# AVR16EB14 device description
Architecture: AVR8X; Family: AVREB
Registers are 8-bit, read-write, reset 0x0 unless marked. A register's access mark holds for its fields unless they carry their own. Offsets are from the block's base; [hi:lo] are bit positions; 'fields as' and 'values as' point back to an identical list.

## TCF — 24-bit Timer/Counter for frequency generation
Instances: TCF0 0x0C00
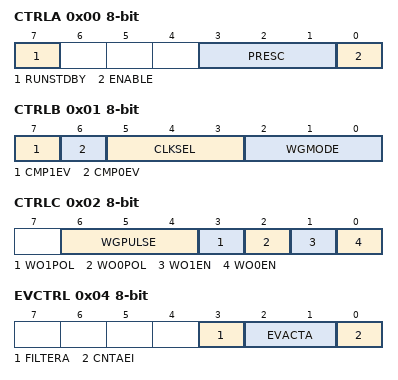
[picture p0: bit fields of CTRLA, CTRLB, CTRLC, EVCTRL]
0x00 CTRLA — Control A
  [7] RUNSTDBY — Run Standby
  [3:1] PRESC — Clock Prescaler
    0=DIV1 (Runs directly on Clock Source); 1=DIV2 (Divide clock source by 2); 2=DIV4 (Divide clock source by 4); 3=DIV8 (Divide clock source by 8); 4=DIV16 (Divide clock source by 16); 5=DIV32 (Divide clock source by 32); 6=DIV64 (Divide clock source by 64); 7=DIV128 (Divide clock source by 128)
  [0] ENABLE
0x01 CTRLB — Control B
  [7] CMP1EV — Compare 1 Event Generation
    0=PULSE (Event is generated as pulse); 1=WAVEFORM (Waveform is used as event output)
  [6] CMP0EV — Compare 0 Event Generation
    values as CMP1EV
  [5:3] CLKSEL — Clock Select
    0=CLKPER (Peripheral Clock); 1=EVENT (Event as clock source); 2=OSCHF (Internal High Frequency Oscillator); 3=OSC32K (Internal 32.768 kHz Oscillator); 5=PLL
  [2:0] WGMODE — Waveform Generation Mode
    0=FRQ (Frequency); 1=NCOPF (Numerically Controlled Oscillator Pulse-Frequency); 2=NCOFDC (Numerically Controlled Oscillator Fixed Duty Cycle); 7=PWM8 (8-bit PWM)
0x02 CTRLC — Control C
  [6:4] WGPULSE — Waveform Generation Pulse Length
    0=CLK1 (High pulse duration is 1 clock period); 1=CLK2 (High pulse duration is 2 clock period); 2=CLK4 (High pulse duration is 4 clock period); 3=CLK8 (High pulse duration is 8 clock period); 4=CLK16 (High pulse duration is 16 clock period); 5=CLK32 (High pulse duration is 32 clock period); 6=CLK64 (High pulse duration is 64 clock period); 7=CLK128 (High pulse duration is 128 clock period)
  [3] WO1POL — Waveform Output 1 Polarity
    0=NORMAL (Waveform output set on update and cleared on match); 1=INVERSE (Waveform output cleared on update and set on match)
  [2] WO0POL — Waveform Output 0 Polarity
    values as WO1POL
  [1] WO1EN — Waveform Output 1 Enable
  [0] WO0EN — Waveform Output 0 Enable
0x03 CTRLD — Control D
  [1:0] CMD — Command
    0=NONE (No command); 1=UPDATE (Force update); 2=RESTART (Force restart)
0x04 EVCTRL — Event Control
  [3] FILTERA — Event A Filter
  [2:1] EVACTA — Event Action A
    0=RESTART (Restart Counter); 1=BLANK (Mask waveform output to '0')
  [0] CNTAEI — Event A Input Enable
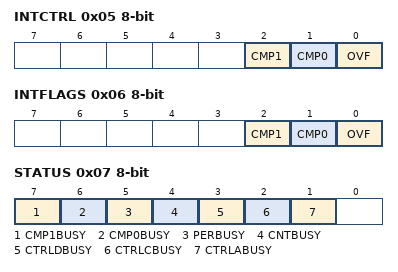
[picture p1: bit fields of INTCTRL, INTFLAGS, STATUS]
0x05 INTCTRL — Interrupt Control
  [2] CMP1 — Compare 1 Interrupt Enable
  [1] CMP0 — Compare 0 Interrupt Enable
  [0] OVF — Overflow
0x06 INTFLAGS — Interrupt Flags
  [2] CMP1 — Compare 1 Flag
  [1] CMP0 — Compare 0 Flag
  [0] OVF — Overflow Flag
0x07 STATUS ro
  [7] CMP1BUSY — Compare 1 Synchronization Busy
  [6] CMP0BUSY — Compare 0 Synchronization Busy
  [5] PERBUSY — Period Synchronization Busy
  [4] CNTBUSY — Counter Synchronization Busy
  [3] CTRLDBUSY — Control D Synchronization Busy
  [2] CTRLCBUSY — Control B Synchronization Busy
  [1] CTRLABUSY — Control A Synchronization Busy
0x0D DBGCTRL — Debug Control
  [0] DBGRUN — Debug Run
0x10 CNT 32-bit — Count
  [23:0] CNT — Counter
0x14 CMP 32-bit — Compare
  [23:0] CMP

## TWI — Two-Wire Interface
Instances: TWI0 0x0900
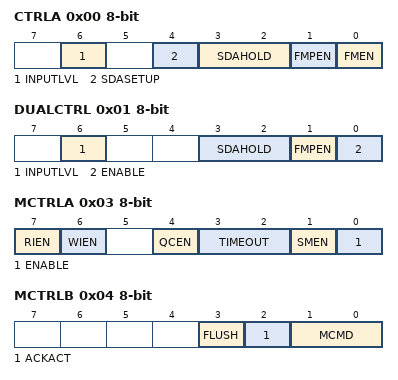
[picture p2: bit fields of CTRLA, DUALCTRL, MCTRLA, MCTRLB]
0x00 CTRLA — Control A
  [6] INPUTLVL — Input voltage transition level
    0=I2C (I2C input voltage transition level); 1=SMBUS (SMBus 3.0 input voltage transition level)
  [4] SDASETUP — SDA Setup Time
    0=4CYC (SDA setup time is four clock cycles); 1=8CYC (SDA setup time is eight clock cycle)
  [3:2] SDAHOLD — SDA Hold Time
    0=OFF (No SDA Hold Delay); 1=50NS (Short SDA hold time); 2=300NS (Meets SMBUS 2.0 specification under typical conditions); 3=500NS (Meets SMBUS 2.0 specificaiton across all corners)
  [1] FMPEN — Fast-mode Plus Enable
    0=OFF (Operating in Standard-mode or Fast-mode); 1=ON (Operating in Fast-mode Plus)
  [0] FMEN — Fast-mode Enable
    0=OFF (SCL duty cycle operating according to Sm specification); 1=ON (SCL duty cycle operating according to Fm specification)
0x01 DUALCTRL — Dual Mode Control
  [6] INPUTLVL — Input voltage transition level
    values as CTRLA.INPUTLVL
  [3:2] SDAHOLD — SDA Hold Time
    values as CTRLA.SDAHOLD
  [1] FMPEN — Fast-mode Plus Enable
    values as CTRLA.FMPEN
  [0] ENABLE
0x02 DBGCTRL — Debug Control
  [0] DBGRUN — Debug Run
    0=HALT (The peripheral is halted in Break Debug mode and ignores events); 1=RUN (The peripheral will continue to run in Break Debug mode when the CPU is halted)
0x03 MCTRLA — Host Control A
  [7] RIEN — Read Interrupt Enable
  [6] WIEN — Write Interrupt Enable
  [4] QCEN — Quick Command Enable
  [3:2] TIMEOUT — Inactive Bus Time-Out
    0=DISABLED (Bus time-out disabled. I2C.); 1=50US (50us - SMBus); 2=100US; 3=200US
  [1] SMEN — Smart Mode Enable
  [0] ENABLE
0x04 MCTRLB — Host Control B
  [3] FLUSH
  [2] ACKACT — Acknowledge Action
    0=ACK (Send ACK); 1=NACK (Send NACK)
  [1:0] MCMD — Command
    0=NOACT (No action); 1=REPSTART (Execute Acknowledge Action followed by repeated Start.); 2=RECVTRANS (Execute Acknowledge Action followed by a byte read/write operation. Read/write is defined by DIR.); 3=STOP (Execute Acknowledge Action followed by issuing a Stop condition.)
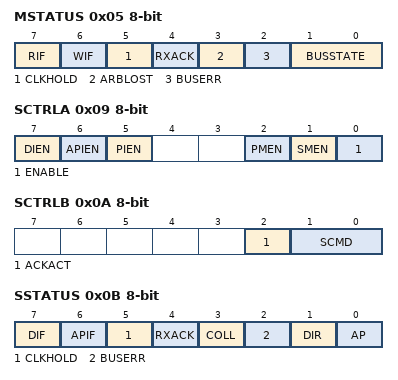
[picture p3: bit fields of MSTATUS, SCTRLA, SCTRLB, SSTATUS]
0x05 MSTATUS — Host STATUS
  [7] RIF — Read Interrupt Flag
  [6] WIF — Write Interrupt Flag
  [5] CLKHOLD — Clock Hold
  [4] RXACK ro — Received Acknowledge
  [3] ARBLOST — Arbitration Lost
  [2] BUSERR — Bus Error
  [1:0] BUSSTATE
    0=UNKNOWN (Unknown bus state); 1=IDLE (Bus is idle); 2=OWNER (This TWI controls the bus); 3=BUSY (The bus is busy)
0x06 MBAUD — Host Baud Rate
  [7:0] BAUD — Baud Rate
0x07 MADDR — Host Address
  [7:0] ADDR — Address
0x08 MDATA — Host Data
  [7:0] DATA
0x09 SCTRLA — Client Control A
  [7] DIEN — Data Interrupt Enable
  [6] APIEN — Address or Stop Interrupt Enable
  [5] PIEN — Stop Interrupt Enable
  [2] PMEN — Address Recognition Mode
  [1] SMEN — Smart Mode Enable
  [0] ENABLE
0x0A SCTRLB — Client Control B
  [2] ACKACT — Acknowledge Action
    0=ACK (Send ACK); 1=NACK (Send NACK)
  [1:0] SCMD — Command
    0=NOACT (No Action); 2=COMPTRANS (Complete transaction); 3=RESPONSE (Used in response to an interrupt)
0x0B SSTATUS — Client Status
  [7] DIF ro — Data Interrupt Flag
  [6] APIF ro — Address or Stop Interrupt Flag
  [5] CLKHOLD ro — Clock Hold
  [4] RXACK ro — Received Acknowledge
  [3] COLL — Collision
  [2] BUSERR — Bus Error
  [1] DIR ro — Read/Write Direction
  [0] AP ro — Address or Stop
    0=STOP (A Stop condition generated the interrupt on APIF flag); 1=ADR (Address detection generated the interrupt on APIF flag)
0x0C SADDR — Client Address
  [7:0] ADDR — Address
0x0D SDATA — Client Data
  [7:0] DATA
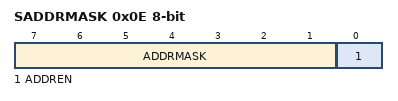
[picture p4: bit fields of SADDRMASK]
0x0E SADDRMASK — Client Address Mask
  [7:1] ADDRMASK — Address Mask
  [0] ADDREN — Address Mask Enable
